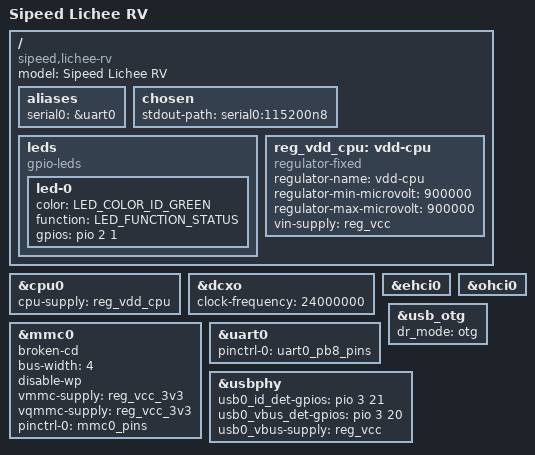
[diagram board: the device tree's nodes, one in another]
// SPDX-License-Identifier: (GPL-2.0+ OR MIT)
// Copyright (C) 2022 Jisheng Zhang <jszhang@kernel.org>
// Copyright (C) 2022 Samuel Holland <samuel@sholland.org>

#include <dt-bindings/gpio/gpio.h>
#include <dt-bindings/leds/common.h>

/dts-v1/;

#include "sun20i-d1.dtsi"
#include "sun20i-common-regulators.dtsi"

/ {
	model = "Sipeed Lichee RV";
	compatible = "sipeed,lichee-rv", "allwinner,sun20i-d1";

	aliases {
		serial0 = &uart0;
	};

	chosen {
		stdout-path = "serial0:115200n8";
	};

	leds {
		compatible = "gpio-leds";

		led-0 {
			color = <LED_COLOR_ID_GREEN>;
			function = LED_FUNCTION_STATUS;
			gpios = <&pio 2 1 GPIO_ACTIVE_HIGH>; /* PC1 */
		};
	};

	reg_vdd_cpu: vdd-cpu {
		compatible = "regulator-fixed";
		regulator-name = "vdd-cpu";
		regulator-min-microvolt = <900000>;
		regulator-max-microvolt = <900000>;
		vin-supply = <&reg_vcc>;
	};
};

&cpu0 {
	cpu-supply = <&reg_vdd_cpu>;
};

&dcxo {
	clock-frequency = <24000000>;
};

&ehci0 {
	status = "okay";
};

&mmc0 {
	broken-cd;
	bus-width = <4>;
	disable-wp;
	vmmc-supply = <&reg_vcc_3v3>;
	vqmmc-supply = <&reg_vcc_3v3>;
	pinctrl-0 = <&mmc0_pins>;
	pinctrl-names = "default";
	status = "okay";
};

&ohci0 {
	status = "okay";
};

&uart0 {
	pinctrl-0 = <&uart0_pb8_pins>;
	pinctrl-names = "default";
	status = "okay";
};

&usb_otg {
	dr_mode = "otg";
	status = "okay";
};

&usbphy {
	usb0_id_det-gpios = <&pio 3 21 GPIO_ACTIVE_HIGH>; /* PD21 */
	usb0_vbus_det-gpios = <&pio 3 20 GPIO_ACTIVE_HIGH>; /* PD20 */
	usb0_vbus-supply = <&reg_vcc>;
	status = "okay";
};
